# A31G11x_series register map
Vendor: ABOV Semiconductor Co., Ltd.; Series: A31G11x_series; File version: 1.0
CPU: CM0PLUS r0p1, little endian, no MPU, no FPU, VTOR, 2 interrupt priority bits
Registers are 32-bit, read-write, reset 0x0 unless marked. A register's access mark holds for its fields unless they carry their own. Offsets are from the block's base; [hi:lo] are bit positions.

## SCUCC — CHIP CONFIGURATION
Base 0x4000F000
0x00 SCU_VENDORID ro reset 0x41424F56 — Vendor Identification Register
  [31:0] VENDID — Vendor Identification bits
0x04 SCU_CHIPID ro reset 0x4D31F000 — Chip Identification Register
  [31:0] CHIPID — Chip Identification bits. 0x4D31F000: 32k bytes flash memory for program 0x4D31F001: 16k bytes flash memory for program
0x08 SCU_REVNR ro — Revision Number Register
  [7:0] REVNO — Chip Revision Number. These bits are fixed by manufacturer.
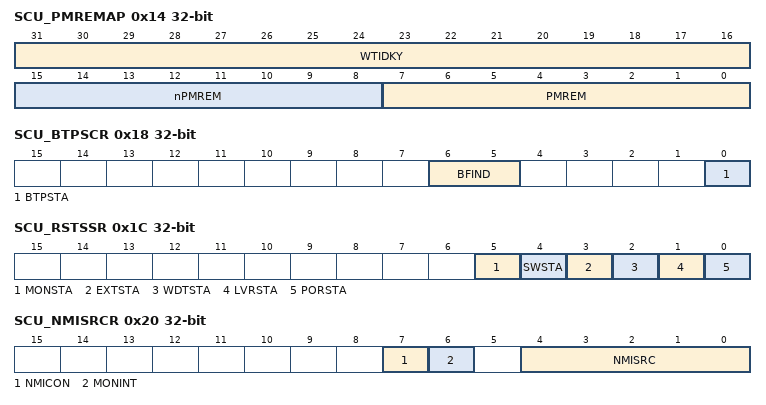
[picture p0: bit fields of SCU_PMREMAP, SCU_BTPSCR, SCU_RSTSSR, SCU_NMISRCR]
0x14 SCU_PMREMAP — Program Memory Remap Register
  [31:16] WTIDKY wo — Write Identification Key. On writes, write 0xE2F1 to these bits, otherwise the write is ignored.
  [15:8] nPMREM wo — Write Complement Key. On writes, write the complement value of PMREM[7:0], otherwise the write is ignored.
    150=REMAP_BOOTROM (Boot ROM is re-mapped to address 0x00000000.); 0=REMAP_FLASH (Flash memory is re-mapped to address 0x00000000.)
  [7:0] PMREM — Program Memory Remap bits
    105=REMAP_BOOTROM (Boot ROM is re-mapped to address 0x00000000.); 0=REMAP_FLASH (Flash memory is re-mapped to address 0x00000000.)
0x18 SCU_BTPSCR — Boot Pin Status and Control Register
  [6:5] BFIND — BOOT Pin Function Indicator bits. The BFIND[1:0] bits are cleared to "00b" by POR, the BFIND[1] bit is cleared to "0b" by nRESET, and the bits are not cleared by other system reset. One of the two of the following must be set in the BFIND[1:0] bits to check whether ISP is needed or not.
    2=CHK_NRST_POR (Check the BOOT pin when a system reset occurs by nRESET including POR.); 3=CHK_POR_ONLY (Check the BOOT pin when a system reset occurs only by POR.)
  [0] BTPSTA ro — BOOT Pin Status bit
    0=LOW_LEVEL_BOOT_PIN (The BOOT pin is low level.); 1=HIGH_LEVEL_BOOT_PIN (The BOOT pin is high level.)
0x1C SCU_RSTSSR — Reset Source Status Register
  [5] MONSTA — Clock Monitoring Reset Status bit
  [4] SWSTA — Software Reset Status bit
  [3] EXTSTA — External Pin Reset Status bit
  [2] WDTSTA — Watch-dog Timer Reset Status bit
  [1] LVRSTA — LVR Reset Status bit
  [0] PORSTA — POR Reset Status bit
0x20 SCU_NMISRCR — NMI Source Selection Register
  [7] NMICON — Non-Maskable Interrupt (NMI) Control bit
  [6] MONINT — Clock Monitoring Interrupt Selection bit
  [4:0] NMISRC — Non-Maskable Interrupt Source Selection bits. Select one of the priority levels 0 to 31 for NMI source.
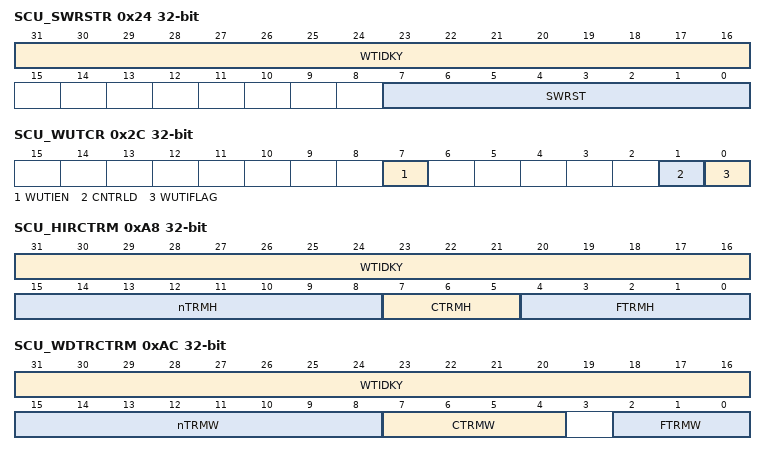
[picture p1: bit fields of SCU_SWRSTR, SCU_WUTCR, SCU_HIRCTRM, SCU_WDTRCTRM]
0x24 SCU_SWRSTR wo — Software Reset Register
  [31:16] WTIDKY — Write Identification Key On writes, write 0x9EB3 to these bits, otherwise the write is ignored.
  [7:0] SWRST — Software Reset bits (System Reset) 0x2D = A software reset will be generated for all peripheral and core. Others = No effect
0x28 SCU_SRSTVR ro reset 0x55 — System Reset Validation Register
  [7:0] VALID — System Reset Validation bits
0x2C SCU_WUTCR — Wake-up Timer Control Register
  [7] WUTIEN — Wake-up Timer Interrupt Enable bit
  [1] CNTRLD — Counter Reload bit
  [0] WUTIFLAG — Wake-up Timer Interrupt Flag bit
0x30 SCU_WUTDR reset 0x138 — Wake-up Timer Data Register
  [15:0] DATA — Wake-up Timer Data bits. The range is 0x0000 to 0xFFFF.
0x40 SCU_CNFWP0 ro reset 0x6 (reset mask 0xFF) — Configure Option Erase/Write Protection 0 Register
0x44 SCU_CNFRDP ro (reset mask 0x3) — Read Protection Configure Register
0x48 SCU_CNFWDT ro (reset mask 0xFFF7) — Watch-dog Timer Configure Register
0x4C SCU_CNFLVR ro (reset mask 0xFF0F) — Low Voltage Reset Configure Register
0x50 SCU_CNFWP1 ro (reset mask 0x7) — Configure Option Erase/Write Protection 1 Register
0x60 SCU_CNFFMWP1 ro (reset mask 0xFFFF) — Flash Memory Erase/Write Protection Configure Register 1
0xA8 SCU_HIRCTRM — High Frequency Internal RC Trim Register (HIRCNFIG)
  [31:16] WTIDKY wo — Write Identification Key. On writes, write 0xA6B5 to these bits, otherwise the write is ignored.
  [15:8] nTRMH wo — Write Complement Key. On writes, write the complement value of LSB, otherwise the write is ignored.
  [7:5] CTRMH ro — Factory HIRC Coarse Trim bits. These bits are fixed by manufacturer and read from "Configure Option Page 0" when a system reset occurs.
  [4:0] FTRMH — Factory HIRC Fine Trim bits. These bits are fixed by manufacturer and read from "Configure Option Page 0" when a system reset occurs. These bits provide a user-programmable trimming value on operation. The range is -16 to +15, the FTRMH[4] is sign bit, and the frequency is changed by 140kHz step-by-step.
0xAC SCU_WDTRCTRM — Watch-dog Timer RC Trim Register (WDTRCNFIG)
  [31:16] WTIDKY wo — Write Identification Key. On writes, write 0x4C3D to these bits, otherwise the write is ignored.
  [15:8] nTRMW wo — Write Complement Key. On writes, write the complement value of TRMW[7:0], otherwise the write is ignored.
  [7:4] CTRMW — Factory WDTRC Coarse Trim bits. These bits are fixed by manufacturer and read from "Configure Option Page 0" when a system reset occurs. These bits provide a user-programmable trimming value on operation. The range is -8 to +7, the CTRMW[3] is sign bit, and the frequency is changed by 3.2kHz step-by-step.
  [2:0] FTRMW — Factory WDTRC Fine Trim bits. These bits are fixed by manufacturer and read from "Configure Option Page 0" when a system reset occurs. These bits provide a userprogrammable trimming value on operation. The range is -4 to +3, the FTRMW[2] is sign bit, and the frequency is changed by 800Hz step-by-step.
